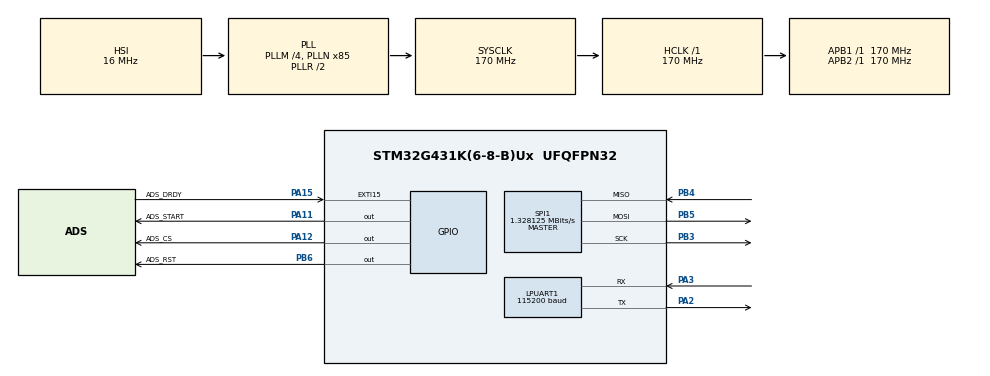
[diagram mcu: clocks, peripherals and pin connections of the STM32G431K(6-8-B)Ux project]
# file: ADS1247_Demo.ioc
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LPUART1.BaudRate=115200
Mcu.Family=STM32G4
Mcu.Name=STM32G431K(6-8-B)Ux
Mcu.Package=UFQFPN32
NVIC.EXTI15_10_IRQn=true\:0\:0\:false\:false\:true\:true\:true\:true
NVIC.PriorityGroup=NVIC_PRIORITYGROUP_4
NVIC.TIM7_IRQn=true\:0\:0\:false\:false\:true\:true\:true\:true
PA11.GPIO_Label=ADS_START
PA11.Signal=GPIO_Output
PA12.GPIO_Label=ADS_CS
PA12.Signal=GPIO_Output
PA13.Mode=Serial_Wire
PA13.Signal=SYS_JTMS-SWDIO
PA14.Mode=Serial_Wire
PA14.Signal=SYS_JTCK-SWCLK
PA15.GPIO_Label=ADS_DRDY
PA15.Signal=GPXTI15
PA2.Mode=Asynchronous
PA2.Signal=LPUART1_TX
PA3.Mode=Asynchronous
PA3.Signal=LPUART1_RX
PB3.Mode=Full_Duplex_Master
PB3.Signal=SPI1_SCK
PB4.Mode=Full_Duplex_Master
PB4.Signal=SPI1_MISO
PB5.Mode=Full_Duplex_Master
PB5.Signal=SPI1_MOSI
PB6.GPIO_Label=ADS_RST
PB6.Signal=GPIO_Output
ProjectManager.HeapSize=0x200
ProjectManager.StackSize=0x400
ProjectManager.TargetToolchain=MDK-ARM V5
RCC.ADC12Freq_Value=170000000
RCC.AHBFreq_Value=170000000
RCC.APB1Freq_Value=170000000
RCC.APB1TimFreq_Value=170000000
RCC.APB2Freq_Value=170000000
RCC.APB2TimFreq_Value=170000000
RCC.CortexFreq_Value=170000000
RCC.EXTERNAL_CLOCK_VALUE=12288000
RCC.HCLKFreq_Value=170000000
RCC.HSE_VALUE=8000000
RCC.HSI48_VALUE=48000000
RCC.HSI_VALUE=16000000
RCC.LSE_VALUE=32768
RCC.PLLM=RCC_PLLM_DIV4
RCC.PLLN=85
RCC.SYSCLKFreq_VALUE=170000000
RCC.SYSCLKSource=RCC_SYSCLKSOURCE_PLLCLK
RCC.USBFreq_Value=170000000
RCC.VCOOutputFreq_Value=340000000
SPI1.BaudRatePrescaler=SPI_BAUDRATEPRESCALER_128
SPI1.CLKPhase=SPI_PHASE_2EDGE
SPI1.CalculateBaudRate=1.328125 MBits/s
SPI1.DataSize=SPI_DATASIZE_8BIT
SPI1.Direction=SPI_DIRECTION_2LINES
SPI1.Mode=SPI_MODE_MASTER
SPI1.VirtualType=VM_MASTER
VP_SYS_VS_DBSignals.Mode=DisableDeadBatterySignals
VP_TIM7_VS_ClockSourceINT.Mode=Enable_Timer
board=custom

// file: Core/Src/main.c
/* USER CODE BEGIN Header */
/**
  ******************************************************************************
  * @file           : main.c
  * @brief          : Main program body
  ******************************************************************************
  * @attention
  *
  * Copyright (c) 2025 STMicroelectronics.
  * All rights reserved.
  *
  * This software is licensed under terms that can be found in the LICENSE file
  * in the root directory of this software component.
  * If no LICENSE file comes with this software, it is provided AS-IS.
  *
  ******************************************************************************
  */
/* USER CODE END Header */
#include "main.h"
#include "usart.h"
#include "spi.h"
#include "tim.h"
#include "gpio.h"

/* USER CODE BEGIN Includes */
#include "M_Flag.h"
/* USER CODE END Includes */

void SystemClock_Config(void);

int main(void)
{

  /* MCU Configuration--------------------------------------------------------*/

  /* Reset of all peripherals, Initializes the Flash interface and the Systick. */
  HAL_Init();

  /* Configure the system clock */
  SystemClock_Config();

  /* Initialize all configured peripherals */
  MX_GPIO_Init();
  MX_SPI1_Init();
  MX_TIM7_Init();
  MX_LPUART1_UART_Init();
  /* USER CODE BEGIN 2 */
  ADS1247_Config_t conf = {
      .spi = &hspi1,
      .CS = {ADS_CS_GPIO_Port, ADS_CS_Pin},
      .ReSet = {ADS_RST_GPIO_Port, ADS_RST_Pin},
      .Start = {ADS_START_GPIO_Port, ADS_START_Pin},
      .Timeout = 100,
  };
  ADS1247_CreateDevice(&ads1247,&conf);
  /* USER CODE END 2 */

  /* Infinite loop */
  while (1)
  {
    ADS1247_getADC(&ads1247,&ADS_adc);
  }
}

void SystemClock_Config(void)
{
  RCC_OscInitTypeDef RCC_OscInitStruct = {0};
  RCC_ClkInitTypeDef RCC_ClkInitStruct = {0};

  /** Configure the main internal regulator output voltage
  */
  HAL_PWREx_ControlVoltageScaling(PWR_REGULATOR_VOLTAGE_SCALE1_BOOST);

  /** Initializes the RCC Oscillators according to the specified parameters
  * in the RCC_OscInitTypeDef structure.
  */
  RCC_OscInitStruct.OscillatorType = RCC_OSCILLATORTYPE_HSI;
  RCC_OscInitStruct.HSIState = RCC_HSI_ON;
  RCC_OscInitStruct.HSICalibrationValue = RCC_HSICALIBRATION_DEFAULT;
  RCC_OscInitStruct.PLL.PLLState = RCC_PLL_ON;
  RCC_OscInitStruct.PLL.PLLSource = RCC_PLLSOURCE_HSI;
  RCC_OscInitStruct.PLL.PLLM = RCC_PLLM_DIV4;
  RCC_OscInitStruct.PLL.PLLN = 85;
  RCC_OscInitStruct.PLL.PLLP = RCC_PLLP_DIV2;
  RCC_OscInitStruct.PLL.PLLQ = RCC_PLLQ_DIV2;
  RCC_OscInitStruct.PLL.PLLR = RCC_PLLR_DIV2;
  if (HAL_RCC_OscConfig(&RCC_OscInitStruct) != HAL_OK)
  {
    Error_Handler();
  }

  /** Initializes the CPU, AHB and APB buses clocks
  */
  RCC_ClkInitStruct.ClockType = RCC_CLOCKTYPE_HCLK|RCC_CLOCKTYPE_SYSCLK
                              |RCC_CLOCKTYPE_PCLK1|RCC_CLOCKTYPE_PCLK2;
  RCC_ClkInitStruct.SYSCLKSource = RCC_SYSCLKSOURCE_PLLCLK;
  RCC_ClkInitStruct.AHBCLKDivider = RCC_SYSCLK_DIV1;
  RCC_ClkInitStruct.APB1CLKDivider = RCC_HCLK_DIV1;
  RCC_ClkInitStruct.APB2CLKDivider = RCC_HCLK_DIV1;

  if (HAL_RCC_ClockConfig(&RCC_ClkInitStruct, FLASH_LATENCY_4) != HAL_OK)
  {
    Error_Handler();
  }
}

void Error_Handler(void)
{
  __disable_irq();
  while (1)
  {
  }
}
